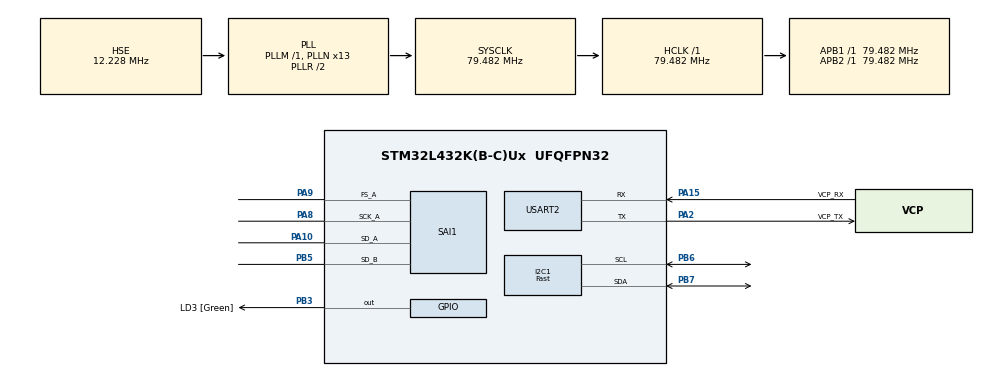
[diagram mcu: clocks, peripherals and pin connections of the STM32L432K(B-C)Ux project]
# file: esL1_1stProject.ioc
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Dma.Request0=SAI1_A
Dma.Request1=SAI1_B
Dma.SAI1_A.0.Direction=DMA_MEMORY_TO_PERIPH
Dma.SAI1_A.0.Instance=DMA2_Channel1
Dma.SAI1_A.0.MemDataAlignment=DMA_MDATAALIGN_HALFWORD
Dma.SAI1_A.0.MemInc=DMA_MINC_ENABLE
Dma.SAI1_A.0.Mode=DMA_CIRCULAR
Dma.SAI1_A.0.PeriphDataAlignment=DMA_PDATAALIGN_HALFWORD
Dma.SAI1_A.0.PeriphInc=DMA_PINC_DISABLE
Dma.SAI1_A.0.Priority=DMA_PRIORITY_LOW
Dma.SAI1_B.1.Direction=DMA_PERIPH_TO_MEMORY
Dma.SAI1_B.1.Instance=DMA2_Channel2
Dma.SAI1_B.1.MemDataAlignment=DMA_MDATAALIGN_HALFWORD
Dma.SAI1_B.1.MemInc=DMA_MINC_ENABLE
Dma.SAI1_B.1.Mode=DMA_CIRCULAR
Dma.SAI1_B.1.PeriphDataAlignment=DMA_PDATAALIGN_HALFWORD
Dma.SAI1_B.1.PeriphInc=DMA_PINC_DISABLE
Dma.SAI1_B.1.Priority=DMA_PRIORITY_LOW
I2C1.I2C_Speed_Mode=I2C_Fast
I2C1.Timing=0x00F12980
Mcu.Family=STM32L4
Mcu.Name=STM32L432K(B-C)Ux
Mcu.Package=UFQFPN32
NVIC.DMA2_Channel1_IRQn=true\:0\:0\:false\:false\:true\:false\:true\:true
NVIC.DMA2_Channel2_IRQn=true\:0\:0\:false\:false\:true\:false\:true\:true
NVIC.PriorityGroup=NVIC_PRIORITYGROUP_4
PA0.GPIO_Label=MCO [High speed clock in]
PA0.Mode=HSE-External-Clock-Source-for-LittleOrca
PA0.Signal=RCC_CK_IN
PA10.Mode=SAI_A_Master
PA10.Signal=SAI1_SD_A
PA13\ (JTMS-SWDIO).GPIO_Label=SWDIO
PA13\ (JTMS-SWDIO).Mode=Serial_Wire
PA13\ (JTMS-SWDIO).Signal=SYS_JTMS-SWDIO
PA14\ (JTCK-SWCLK).GPIO_Label=SWCLK
PA14\ (JTCK-SWCLK).Mode=Serial_Wire
PA14\ (JTCK-SWCLK).Signal=SYS_JTCK-SWCLK
PA15\ (JTDI).GPIO_Label=VCP_RX
PA15\ (JTDI).Mode=Asynchronous
PA15\ (JTDI).Signal=USART2_RX
PA2.GPIO_Label=VCP_TX
PA2.Mode=Asynchronous
PA2.Signal=USART2_TX
PA8.Mode=SAI_A_Master
PA8.Signal=SAI1_SCK_A
PA9.Mode=SAI_A_Master
PA9.Signal=SAI1_FS_A
PB3\ (JTDO-TRACESWO).GPIO_Label=LD3 [Green]
PB3\ (JTDO-TRACESWO).Signal=GPIO_Output
PB5.Mode=SAI_B_SyncSlave
PB5.Signal=SAI1_SD_B
PB6.Mode=I2C
PB6.Signal=I2C1_SCL
PB7.Mode=I2C
PB7.Signal=I2C1_SDA
PC14-OSC32_IN\ (PC14).Mode=LSE-External-Oscillator
PC14-OSC32_IN\ (PC14).Signal=RCC_OSC32_IN
PC15-OSC32_OUT\ (PC15).Mode=LSE-External-Oscillator
PC15-OSC32_OUT\ (PC15).Signal=RCC_OSC32_OUT
ProjectManager.HeapSize=0x200
ProjectManager.StackSize=0x400
ProjectManager.TargetToolchain=CMake
RCC.ADCFreq_Value=97824000
RCC.AHBFreq_Value=79482000
RCC.APB1Freq_Value=79482000
RCC.APB1TimFreq_Value=79482000
RCC.APB2Freq_Value=79482000
RCC.APB2TimFreq_Value=79482000
RCC.CortexFreq_Value=79482000
RCC.HCLKFreq_Value=79482000
RCC.HSE_VALUE=12228000
RCC.HSI16_VALUE=16000000
RCC.HSI48_VALUE=48000000
RCC.HSI_VALUE=16000000
RCC.MSI_VALUE=4000000
RCC.PLLMUL=RCC_PLLMUL_4
RCC.PLLN=13
RCC.PLLSAI1N=16
RCC.PLLSAI1P=RCC_PLLP_DIV8
RCC.PLLSourceVirtual=RCC_PLLSOURCE_HSE
RCC.SYSCLKFreq_VALUE=79482000
RCC.SYSCLKSource=RCC_SYSCLKSOURCE_PLLCLK
RCC.USBFreq_Value=97824000
RCC.VCOOutputFreq_Value=158964000
SAI1.AudioFrequency-SAI_A_Master=SAI_AUDIO_FREQUENCY_48K
SAI1.ErrorAudioFreq-SAI_A_Master=-0.48 %
SAI1.InitProtocol-SAI_A_Master=Enable
SAI1.InitProtocol-SAI_B_SyncSlave=Enable
SAI1.Instance-SAI_A_Master=SAI$Index_Block_A
SAI1.Instance-SAI_B_SyncSlave=SAI$Index_Block_B
SAI1.MClockEnable-SAI_A_Master=SAI_MASTERCLOCK_DISABLE
SAI1.RealAudioFreq-SAI_A_Master=47.765 KHz
SAI1.VirtualMode-SAI_A_Master=VM_MASTER
SAI1.VirtualMode-SAI_B_SyncSlave=VM_SLAVE
SAI1.VirtualProtocol-SAI_A_BASIC=VM_BASIC_PROTOCOL
SAI1.VirtualProtocol-SAI_B_BASIC=VM_BASIC_PROTOCOL
USART2.VirtualMode-Asynchronous=VM_ASYNC
VP_SAI1_VP_$IpInstance_SAIA_SAI_BASIC.Mode=SAI_A_BASIC
VP_SAI1_VP_$IpInstance_SAIB_SAI_BASIC.Mode=SAI_B_BASIC
board=NUCLEO-L432KC

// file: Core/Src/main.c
/* USER CODE BEGIN Header */
/**
  ******************************************************************************
  * @file           : main.c
  * @brief          : Main program body
  ******************************************************************************
  * @attention
  *
  * Copyright (c) 2025 STMicroelectronics.
  * All rights reserved.
  *
  * This software is licensed under terms that can be found in the LICENSE file
  * in the root directory of this software component.
  * If no LICENSE file comes with this software, it is provided AS-IS.
  *
  ******************************************************************************
  */
/* USER CODE END Header */
#include "main.h"

/* USER CODE BEGIN Includes */
#include "app_main.h"
/* USER CODE END Includes */

I2C_HandleTypeDef hi2c1;

SAI_HandleTypeDef hsai_BlockA1;
SAI_HandleTypeDef hsai_BlockB1;
DMA_HandleTypeDef hdma_sai1_a;
DMA_HandleTypeDef hdma_sai1_b;

UART_HandleTypeDef huart2;

/* USER CODE BEGIN PV */
int16_t saiTx_buf[SAI_BUF_LEN];
int16_t saiRx_buf[SAI_BUF_LEN];
/* USER CODE END PV */

void SystemClock_Config(void);
void PeriphCommonClock_Config(void);
static void MX_GPIO_Init(void);
static void MX_DMA_Init(void);
static void MX_USART2_UART_Init(void);
static void MX_I2C1_Init(void);
static void MX_SAI1_Init(void);

int main(void)
{

  /* MCU Configuration--------------------------------------------------------*/

  /* Reset of all peripherals, Initializes the Flash interface and the Systick. */
  HAL_Init();

  /* Configure the system clock */
  SystemClock_Config();

  /* Configure the peripherals common clocks */
  PeriphCommonClock_Config();

  /* Initialize all configured peripherals */
  MX_GPIO_Init();
  MX_DMA_Init();
  MX_USART2_UART_Init();
  MX_I2C1_Init();
  MX_SAI1_Init();
  /* USER CODE BEGIN 2 */
  setup();
  HAL_SAI_Transmit_DMA(&hsai_BlockA1, (uint8_t*) saiTx_buf, SAI_BUF_LEN);
  HAL_SAI_Receive_DMA(&hsai_BlockB1, (uint8_t*) saiRx_buf, SAI_BUF_LEN);
  /* USER CODE END 2 */

  /* Infinite loop */
  while (1)
  {

    /* USER CODE BEGIN 3 */
    mainloop();
  }
  /* USER CODE END 3 */
}

void SystemClock_Config(void)
{
  RCC_OscInitTypeDef RCC_OscInitStruct = {0};
  RCC_ClkInitTypeDef RCC_ClkInitStruct = {0};

  /** Configure the main internal regulator output voltage
  */
  if (HAL_PWREx_ControlVoltageScaling(PWR_REGULATOR_VOLTAGE_SCALE1) != HAL_OK)
  {
    Error_Handler();
  }

  /** Initializes the RCC Oscillators according to the specified parameters
  * in the RCC_OscInitTypeDef structure.
  */
  RCC_OscInitStruct.OscillatorType = RCC_OSCILLATORTYPE_HSE;
  RCC_OscInitStruct.HSEState = RCC_HSE_BYPASS;
  RCC_OscInitStruct.PLL.PLLState = RCC_PLL_ON;
  RCC_OscInitStruct.PLL.PLLSource = RCC_PLLSOURCE_HSE;
  RCC_OscInitStruct.PLL.PLLM = 1;
  RCC_OscInitStruct.PLL.PLLN = 13;
  RCC_OscInitStruct.PLL.PLLP = RCC_PLLP_DIV7;
  RCC_OscInitStruct.PLL.PLLQ = RCC_PLLQ_DIV2;
  RCC_OscInitStruct.PLL.PLLR = RCC_PLLR_DIV2;
  if (HAL_RCC_OscConfig(&RCC_OscInitStruct) != HAL_OK)
  {
    Error_Handler();
  }

  /** Initializes the CPU, AHB and APB buses clocks
  */
  RCC_ClkInitStruct.ClockType = RCC_CLOCKTYPE_HCLK|RCC_CLOCKTYPE_SYSCLK
                              |RCC_CLOCKTYPE_PCLK1|RCC_CLOCKTYPE_PCLK2;
  RCC_ClkInitStruct.SYSCLKSource = RCC_SYSCLKSOURCE_PLLCLK;
  RCC_ClkInitStruct.AHBCLKDivider = RCC_SYSCLK_DIV1;
  RCC_ClkInitStruct.APB1CLKDivider = RCC_HCLK_DIV1;
  RCC_ClkInitStruct.APB2CLKDivider = RCC_HCLK_DIV1;

  if (HAL_RCC_ClockConfig(&RCC_ClkInitStruct, FLASH_LATENCY_4) != HAL_OK)
  {
    Error_Handler();
  }
}

void PeriphCommonClock_Config(void)
{
  RCC_PeriphCLKInitTypeDef PeriphClkInit = {0};

  /** Initializes the peripherals clock
  */
  PeriphClkInit.PeriphClockSelection = RCC_PERIPHCLK_SAI1;
  PeriphClkInit.Sai1ClockSelection = RCC_SAI1CLKSOURCE_PLLSAI1;
  PeriphClkInit.PLLSAI1.PLLSAI1Source = RCC_PLLSOURCE_HSE;
  PeriphClkInit.PLLSAI1.PLLSAI1M = 1;
  PeriphClkInit.PLLSAI1.PLLSAI1N = 16;
  PeriphClkInit.PLLSAI1.PLLSAI1P = RCC_PLLP_DIV8;
  PeriphClkInit.PLLSAI1.PLLSAI1Q = RCC_PLLQ_DIV2;
  PeriphClkInit.PLLSAI1.PLLSAI1R = RCC_PLLR_DIV2;
  PeriphClkInit.PLLSAI1.PLLSAI1ClockOut = RCC_PLLSAI1_SAI1CLK;
  if (HAL_RCCEx_PeriphCLKConfig(&PeriphClkInit) != HAL_OK)
  {
    Error_Handler();
  }
}

static void MX_I2C1_Init(void)
{

  hi2c1.Instance = I2C1;
  hi2c1.Init.Timing = 0x00F12980;
  hi2c1.Init.OwnAddress1 = 0;
  hi2c1.Init.AddressingMode = I2C_ADDRESSINGMODE_7BIT;
  hi2c1.Init.DualAddressMode = I2C_DUALADDRESS_DISABLE;
  hi2c1.Init.OwnAddress2 = 0;
  hi2c1.Init.OwnAddress2Masks = I2C_OA2_NOMASK;
  hi2c1.Init.GeneralCallMode = I2C_GENERALCALL_DISABLE;
  hi2c1.Init.NoStretchMode = I2C_NOSTRETCH_DISABLE;
  if (HAL_I2C_Init(&hi2c1) != HAL_OK)
  {
    Error_Handler();
  }

  /** Configure Analogue filter
  */
  if (HAL_I2CEx_ConfigAnalogFilter(&hi2c1, I2C_ANALOGFILTER_ENABLE) != HAL_OK)
  {
    Error_Handler();
  }

  /** Configure Digital filter
  */
  if (HAL_I2CEx_ConfigDigitalFilter(&hi2c1, 0) != HAL_OK)
  {
    Error_Handler();
  }

}

static void MX_SAI1_Init(void)
{

  hsai_BlockA1.Instance = SAI1_Block_A;
  hsai_BlockA1.Init.AudioMode = SAI_MODEMASTER_TX;
  hsai_BlockA1.Init.Synchro = SAI_ASYNCHRONOUS;
  hsai_BlockA1.Init.OutputDrive = SAI_OUTPUTDRIVE_DISABLE;
  hsai_BlockA1.Init.NoDivider = SAI_MASTERDIVIDER_ENABLE;
  hsai_BlockA1.Init.FIFOThreshold = SAI_FIFOTHRESHOLD_EMPTY;
  hsai_BlockA1.Init.AudioFrequency = SAI_AUDIO_FREQUENCY_48K;
  hsai_BlockA1.Init.SynchroExt = SAI_SYNCEXT_DISABLE;
  hsai_BlockA1.Init.MonoStereoMode = SAI_STEREOMODE;
  hsai_BlockA1.Init.CompandingMode = SAI_NOCOMPANDING;
  hsai_BlockA1.Init.TriState = SAI_OUTPUT_NOTRELEASED;
  if (HAL_SAI_InitProtocol(&hsai_BlockA1, SAI_I2S_STANDARD, SAI_PROTOCOL_DATASIZE_16BIT, 2) != HAL_OK)
  {
    Error_Handler();
  }
  hsai_BlockB1.Instance = SAI1_Block_B;
  hsai_BlockB1.Init.AudioMode = SAI_MODESLAVE_RX;
  hsai_BlockB1.Init.Synchro = SAI_SYNCHRONOUS;
  hsai_BlockB1.Init.OutputDrive = SAI_OUTPUTDRIVE_DISABLE;
  hsai_BlockB1.Init.FIFOThreshold = SAI_FIFOTHRESHOLD_EMPTY;
  hsai_BlockB1.Init.SynchroExt = SAI_SYNCEXT_DISABLE;
  hsai_BlockB1.Init.MonoStereoMode = SAI_STEREOMODE;
  hsai_BlockB1.Init.CompandingMode = SAI_NOCOMPANDING;
  hsai_BlockB1.Init.TriState = SAI_OUTPUT_NOTRELEASED;
  if (HAL_SAI_InitProtocol(&hsai_BlockB1, SAI_I2S_STANDARD, SAI_PROTOCOL_DATASIZE_16BIT, 2) != HAL_OK)
  {
    Error_Handler();
  }

}

static void MX_USART2_UART_Init(void)
{

  huart2.Instance = USART2;
  huart2.Init.BaudRate = 115200;
  huart2.Init.WordLength = UART_WORDLENGTH_8B;
  huart2.Init.StopBits = UART_STOPBITS_1;
  huart2.Init.Parity = UART_PARITY_NONE;
  huart2.Init.Mode = UART_MODE_TX_RX;
  huart2.Init.HwFlowCtl = UART_HWCONTROL_NONE;
  huart2.Init.OverSampling = UART_OVERSAMPLING_16;
  huart2.Init.OneBitSampling = UART_ONE_BIT_SAMPLE_DISABLE;
  huart2.AdvancedInit.AdvFeatureInit = UART_ADVFEATURE_NO_INIT;
  if (HAL_UART_Init(&huart2) != HAL_OK)
  {
    Error_Handler();
  }

}

static void MX_DMA_Init(void)
{

  /* DMA controller clock enable */
  __HAL_RCC_DMA2_CLK_ENABLE();

  /* DMA interrupt init */
  /* DMA2_Channel1_IRQn interrupt configuration */
  HAL_NVIC_SetPriority(DMA2_Channel1_IRQn, 0, 0);
  HAL_NVIC_EnableIRQ(DMA2_Channel1_IRQn);
  /* DMA2_Channel2_IRQn interrupt configuration */
  HAL_NVIC_SetPriority(DMA2_Channel2_IRQn, 0, 0);
  HAL_NVIC_EnableIRQ(DMA2_Channel2_IRQn);

}

static void MX_GPIO_Init(void)
{
  GPIO_InitTypeDef GPIO_InitStruct = {0};

  /* GPIO Ports Clock Enable */
  __HAL_RCC_GPIOC_CLK_ENABLE();
  __HAL_RCC_GPIOA_CLK_ENABLE();
  __HAL_RCC_GPIOB_CLK_ENABLE();

  /*Configure GPIO pin Output Level */
  HAL_GPIO_WritePin(LD3_GPIO_Port, LD3_Pin, GPIO_PIN_RESET);

  /*Configure GPIO pin : LD3_Pin */
  GPIO_InitStruct.Pin = LD3_Pin;
  GPIO_InitStruct.Mode = GPIO_MODE_OUTPUT_PP;
  GPIO_InitStruct.Pull = GPIO_NOPULL;
  GPIO_InitStruct.Speed = GPIO_SPEED_FREQ_LOW;
  HAL_GPIO_Init(LD3_GPIO_Port, &GPIO_InitStruct);

}

/* USER CODE BEGIN 4 */

void HAL_SAI_RxCpltCallback(SAI_HandleTypeDef *hsai) {
  process_data(&saiRx_buf[SAI_BUF_LEN/2], &saiTx_buf[SAI_BUF_LEN/2]);
}

void HAL_SAI_RxHalfCpltCallback(SAI_HandleTypeDef *hsai) {
  process_data(&saiRx_buf[0], &saiTx_buf[0]);
}
/* USER CODE END 4 */

void Error_Handler(void)
{
  __disable_irq();
  while (1)
  {
  }
}
